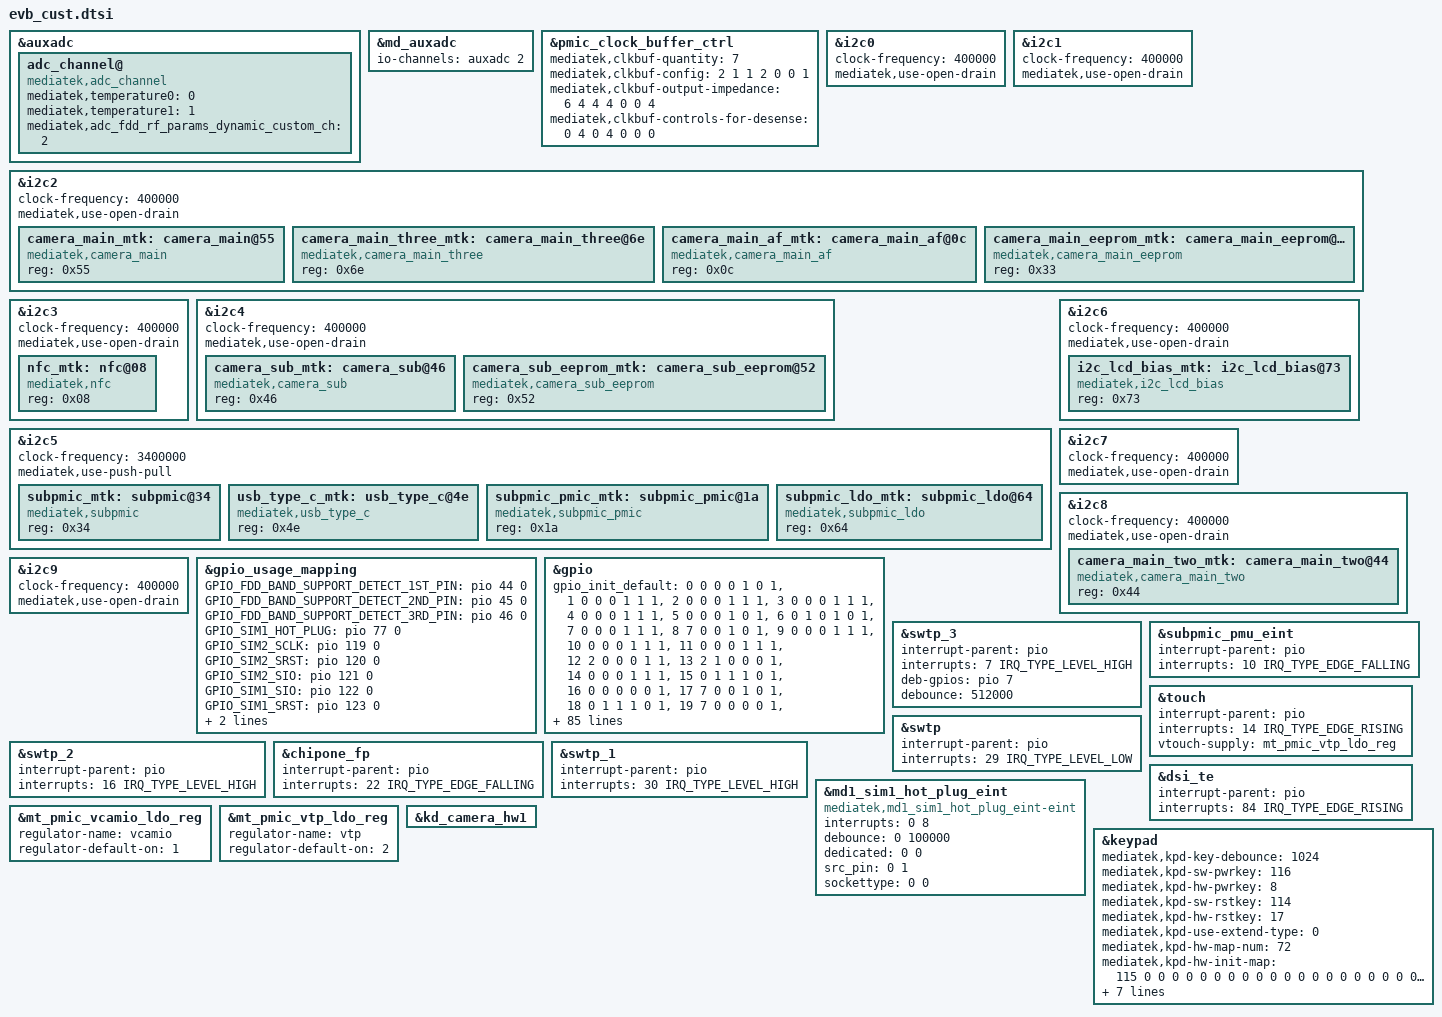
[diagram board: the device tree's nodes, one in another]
/*
 * Generated by MTK SP DrvGen Version: 3.5.160809 for MT6833.
 * 2023-02-21 14:04:30
 * Do Not Modify The File.
 * Copyright Mediatek Inc. (c) 2016.
*/

/*************************
 * ADC DTSI File
*************************/

&auxadc {
	adc_channel@ {
		compatible = "mediatek,adc_channel";
		mediatek,temperature0 = <0>;
		mediatek,temperature1 = <1>;
		mediatek,adc_fdd_rf_params_dynamic_custom_ch = <2>;
		status = "okay";
	};
};
&md_auxadc {
	io-channels = <&auxadc 2>;
};


/*************************
 * CLK_BUF DTSI File
*************************/

&pmic_clock_buffer_ctrl {
	mediatek,clkbuf-quantity = <7>;
	mediatek,clkbuf-config = <2 1 1 2 0 0 1>;
	mediatek,clkbuf-output-impedance = <6 4 4 4 0 0 4>;
	mediatek,clkbuf-controls-for-desense = <0 4 0 4 0 0 0>;
	status = "okay";
};


/*************************
 * I2C DTSI File
*************************/

&i2c0 {
	#address-cells = <1>;
	#size-cells = <0>;
	clock-frequency = <400000>;
	mediatek,use-open-drain;
};

&i2c1 {
	#address-cells = <1>;
	#size-cells = <0>;
	clock-frequency = <400000>;
	mediatek,use-open-drain;
};

&i2c2 {
	#address-cells = <1>;
	#size-cells = <0>;
	clock-frequency = <400000>;
	mediatek,use-open-drain;
	camera_main_mtk:camera_main@55 {
		compatible = "mediatek,camera_main";
		reg = <0x55>;
		status = "okay";
	};

	camera_main_three_mtk:camera_main_three@6e {
		compatible = "mediatek,camera_main_three";
		reg = <0x6e>;
		status = "okay";
	};

	camera_main_af_mtk:camera_main_af@0c {
		compatible = "mediatek,camera_main_af";
		reg = <0x0c>;
		status = "okay";
	};

	camera_main_eeprom_mtk:camera_main_eeprom@33 {
		compatible = "mediatek,camera_main_eeprom";
		reg = <0x33>;
		status = "okay";
	};

};

&i2c3 {
	#address-cells = <1>;
	#size-cells = <0>;
	clock-frequency = <400000>;
	mediatek,use-open-drain;
	nfc_mtk:nfc@08 {
		compatible = "mediatek,nfc";
		reg = <0x08>;
		status = "okay";
	};

};

&i2c4 {
	#address-cells = <1>;
	#size-cells = <0>;
	clock-frequency = <400000>;
	mediatek,use-open-drain;
	camera_sub_mtk:camera_sub@46 {
		compatible = "mediatek,camera_sub";
		reg = <0x46>;
		status = "okay";
	};

	camera_sub_eeprom_mtk:camera_sub_eeprom@52 {
		compatible = "mediatek,camera_sub_eeprom";
		reg = <0x52>;
		status = "okay";
	};

};

&i2c5 {
	#address-cells = <1>;
	#size-cells = <0>;
	clock-frequency = <3400000>;
	mediatek,use-push-pull;
	subpmic_mtk:subpmic@34 {
		compatible = "mediatek,subpmic";
		reg = <0x34>;
		status = "okay";
	};

	usb_type_c_mtk:usb_type_c@4e {
		compatible = "mediatek,usb_type_c";
		reg = <0x4e>;
		status = "okay";
	};

	subpmic_pmic_mtk:subpmic_pmic@1a {
		compatible = "mediatek,subpmic_pmic";
		reg = <0x1a>;
		status = "okay";
	};

	subpmic_ldo_mtk:subpmic_ldo@64 {
		compatible = "mediatek,subpmic_ldo";
		reg = <0x64>;
		status = "okay";
	};

};

&i2c6 {
	#address-cells = <1>;
	#size-cells = <0>;
	clock-frequency = <400000>;
	mediatek,use-open-drain;
	i2c_lcd_bias_mtk:i2c_lcd_bias@73 {
		compatible = "mediatek,i2c_lcd_bias";
		reg = <0x73>;
		status = "okay";
	};

};

&i2c7 {
	#address-cells = <1>;
	#size-cells = <0>;
	clock-frequency = <400000>;
	mediatek,use-open-drain;
};

&i2c8 {
	#address-cells = <1>;
	#size-cells = <0>;
	clock-frequency = <400000>;
	mediatek,use-open-drain;
	camera_main_two_mtk:camera_main_two@44 {
		compatible = "mediatek,camera_main_two";
		reg = <0x44>;
		status = "okay";
	};

};

&i2c9 {
	#address-cells = <1>;
	#size-cells = <0>;
	clock-frequency = <400000>;
	mediatek,use-open-drain;
};



/*************************
 * GPIO DTSI File
*************************/

&gpio_usage_mapping {
	GPIO_FDD_BAND_SUPPORT_DETECT_1ST_PIN = <&pio 44 0>;
	GPIO_FDD_BAND_SUPPORT_DETECT_2ND_PIN = <&pio 45 0>;
	GPIO_FDD_BAND_SUPPORT_DETECT_3RD_PIN = <&pio 46 0>;
	GPIO_SIM1_HOT_PLUG = <&pio 77 0>;
	GPIO_SIM2_SCLK = <&pio 119 0>;
	GPIO_SIM2_SRST = <&pio 120 0>;
	GPIO_SIM2_SIO = <&pio 121 0>;
	GPIO_SIM1_SIO = <&pio 122 0>;
	GPIO_SIM1_SRST = <&pio 123 0>;
	GPIO_SIM1_SCLK = <&pio 124 0>;
	GPIO_RF_PWREN_RST_PIN = <&pio 170 0>;
};

&gpio{
	gpio_init_default = <0 0 0 0 1 0 1>,
		<1 0 0 0 1 1 1>,
		<2 0 0 0 1 1 1>,
		<3 0 0 0 1 1 1>,
		<4 0 0 0 1 1 1>,
		<5 0 0 0 1 0 1>,
		<6 0 1 0 1 0 1>,
		<7 0 0 0 1 1 1>,
		<8 7 0 0 1 0 1>,
		<9 0 0 0 1 1 1>,
		<10 0 0 0 1 1 1>,
		<11 0 0 0 1 1 1>,
		<12 2 0 0 0 1 1>,
		<13 2 1 0 0 0 1>,
		<14 0 0 0 1 1 1>,
		<15 0 1 1 1 0 1>,
		<16 0 0 0 0 0 1>,
		<17 7 0 0 1 0 1>,
		<18 0 1 1 1 0 1>,
		<19 7 0 0 0 0 1>,
		<20 7 0 0 1 0 1>,
		<21 0 1 0 1 0 1>,
		<22 0 0 0 1 0 1>,
		<23 7 0 0 1 0 1>,
		<24 7 0 0 1 0 1>,
		<25 7 0 0 1 0 1>,
		<26 7 0 0 1 0 1>,
		<27 1 0 0 0 0 1>,
		<28 1 0 0 0 0 1>,
		<29 0 0 0 0 0 1>,
		<30 0 0 0 0 0 1>,
		<31 2 1 0 0 0 0>,
		<32 2 1 0 0 0 0>,
		<33 2 1 0 0 0 0>,
		<34 2 0 0 1 0 0>,
		<35 1 0 0 1 1 1>,
		<36 1 0 0 0 0 1>,
		<37 1 0 0 0 0 1>,
		<38 1 0 0 1 1 1>,
		<39 0 0 0 1 1 1>,
		<40 1 0 0 0 0 1>,
		<41 1 0 0 0 0 1>,
		<42 1 0 0 1 0 1>,
		<43 1 0 0 0 0 1>,
		<44 0 0 0 1 0 1>,
		<45 0 0 0 1 0 1>,
		<46 0 0 0 1 0 1>,
		<47 0 0 0 1 0 1>,
		<48 0 0 0 1 0 1>,
		<49 1 0 0 0 0 1>,
		<50 1 0 0 0 0 1>,
		<51 1 0 0 0 0 1>,
		<52 1 0 0 0 0 1>,
		<53 0 1 0 1 0 1>,
		<54 0 1 0 1 0 1>,
		<55 0 1 0 1 0 1>,
		<56 0 1 0 1 0 1>,
		<57 0 0 0 1 0 1>,
		<58 0 1 0 1 0 1>,
		<59 1 0 0 1 0 1>,
		<60 0 1 0 1 0 1>,
		<61 1 0 0 1 1 1>,
		<62 1 0 0 0 0 1>,
		<63 1 0 0 1 1 1>,
		<64 1 0 0 0 0 1>,
		<77 1 0 0 1 1 1>,
		<78 0 0 0 1 0 1>,
		<79 1 0 0 1 1 1>,
		<80 0 1 0 1 0 1>,
		<81 3 0 0 1 0 1>,
		<82 0 1 0 1 0 1>,
		<83 1 0 0 0 0 1>,
		<84 1 0 0 1 0 1>,
		<85 1 0 0 1 0 1>,
		<86 0 0 0 1 0 1>,
		<87 1 1 0 1 0 1>,
		<88 1 1 0 1 0 1>,
		<89 1 1 0 1 0 1>,
		<90 1 1 0 0 0 1>,
		<91 1 1 0 1 0 1>,
		<92 1 1 0 1 0 1>,
		<93 0 1 0 1 0 1>,
		<94 0 1 0 1 0 1>,
		<95 1 0 0 1 0 1>,
		<96 1 0 0 1 0 1>,
		<97 2 1 0 0 0 1>,
		<98 2 1 0 0 0 1>,
		<99 2 0 0 1 1 1>,
		<100 2 0 0 1 1 1>,
		<101 1 0 0 1 1 1>,
		<102 1 0 0 1 1 1>,
		<103 1 0 0 1 1 1>,
		<104 1 0 0 1 1 1>,
		<105 1 0 0 1 1 1>,
		<106 1 0 0 1 1 1>,
		<107 1 0 0 1 1 1>,
		<108 1 0 0 1 1 1>,
		<109 1 0 0 1 1 1>,
		<110 1 0 0 1 1 1>,
		<111 1 0 0 1 1 1>,
		<112 1 0 0 1 1 1>,
		<113 1 0 0 1 1 1>,
		<114 1 0 0 1 1 1>,
		<115 1 0 0 1 0 1>,
		<116 1 0 0 1 0 1>,
		<117 0 0 0 1 0 1>,
		<118 0 0 0 1 0 1>,
		<119 1 0 0 0 0 1>,
		<120 1 0 0 0 0 1>,
		<121 1 0 0 1 1 1>,
		<122 1 0 0 1 1 1>,
		<123 1 0 0 0 0 1>,
		<124 1 0 0 0 0 1>,
		<125 1 0 0 0 0 1>,
		<126 1 0 0 1 1 1>,
		<127 1 0 0 1 1 1>,
		<128 1 0 0 1 1 1>,
		<129 1 0 0 1 1 1>,
		<130 1 0 0 1 1 1>,
		<131 0 1 1 1 0 1>,
		<132 0 0 0 0 0 1>,
		<133 0 1 0 1 0 1>,
		<134 0 1 0 1 0 1>,
		<135 0 1 0 1 0 1>,
		<136 0 1 1 1 0 1>,
		<137 0 1 0 1 0 1>,
		<138 0 1 0 1 0 1>,
		<139 0 1 0 1 0 1>,
		<140 0 1 0 1 0 1>,
		<141 1 0 0 0 0 1>,
		<142 1 0 0 0 0 1>,
		<143 1 0 0 0 0 1>,
		<144 1 0 0 0 0 1>,
		<145 1 0 0 0 0 1>,
		<146 1 0 0 0 0 1>,
		<147 1 0 0 0 0 1>,
		<148 1 0 0 0 0 1>,
		<149 1 0 0 1 0 1>,
		<150 1 0 0 1 0 1>,
		<151 1 0 0 1 0 1>,
		<152 1 0 0 1 0 1>,
		<153 1 0 0 0 0 1>,
		<154 1 0 0 0 0 1>,
		<155 1 0 0 0 0 1>,
		<156 1 0 0 0 0 1>,
		<157 1 0 0 0 0 1>,
		<158 1 0 0 0 0 1>,
		<159 1 0 0 1 0 1>,
		<160 1 0 0 1 0 1>,
		<161 1 0 0 1 0 1>,
		<162 1 0 0 0 0 0>,
		<163 1 0 0 1 0 0>,
		<164 1 0 0 1 0 1>,
		<165 1 0 0 1 0 1>,
		<166 1 0 0 0 0 1>,
		<167 1 0 0 0 0 1>,
		<168 1 0 0 0 0 1>,
		<169 0 0 0 1 0 1>,
		<170 0 1 1 1 0 1>,
		<171 1 0 0 0 0 1>,
		<172 1 0 0 0 0 1>,
		<173 1 0 0 0 0 1>,
		<174 1 0 0 0 0 1>,
		<175 1 0 0 0 0 1>,
		<176 1 0 0 0 0 1>,
		<177 1 0 0 0 0 1>,
		<178 1 0 0 0 0 1>,
		<179 1 0 0 0 0 1>,
		<180 1 0 0 0 0 1>,
		<181 1 0 0 0 0 1>,
		<182 1 0 0 0 0 1>,
		<183 1 0 0 0 0 1>,
		<184 1 0 0 0 0 1>,
		<185 1 0 0 0 0 1>,
		<186 1 0 0 0 0 1>,
		<187 1 0 0 0 0 1>,
		<188 1 0 0 0 0 0>,
		<189 1 0 0 1 0 0>,
		<190 1 0 0 0 0 0>,
		<191 1 0 0 1 0 0>,
		<192 0 0 0 1 0 1>,
		<193 0 0 0 1 0 1>,
		<194 0 0 0 1 0 1>,
		<195 0 0 0 1 0 1>,
		<196 0 0 0 1 0 1>,
		<197 0 0 0 1 0 1>,
		<198 0 0 0 1 0 1>,
		<199 0 0 0 1 0 1>,
		<200 0 0 0 1 0 1>;
};


/*************************
 * EINT DTSI File
*************************/

#include <dt-bindings/interrupt-controller/irq.h>
#include <dt-bindings/interrupt-controller/arm-gic.h>

&swtp_3 {
	interrupt-parent = <&pio>;
	interrupts = <7 IRQ_TYPE_LEVEL_HIGH>;
	deb-gpios = <&pio 7 0>;
	debounce = <512000>;
	status = "okay";
};

&subpmic_pmu_eint {
	interrupt-parent = <&pio>;
	interrupts = <10 IRQ_TYPE_EDGE_FALLING>;
	status = "okay";
};

&touch {
	interrupt-parent = <&pio>;
	interrupts = <14 IRQ_TYPE_EDGE_RISING>;
	status = "okay";
};

&swtp_2 {
	interrupt-parent = <&pio>;
	interrupts = <16 IRQ_TYPE_LEVEL_HIGH>;
	status = "okay";
};

&chipone_fp {
	interrupt-parent = <&pio>;
	interrupts = <22 IRQ_TYPE_EDGE_FALLING>;
	status = "okay";
};

&swtp {
	interrupt-parent = <&pio>;
	interrupts = <29 IRQ_TYPE_LEVEL_LOW>;
	status = "okay";
};

&swtp_1 {
	interrupt-parent = <&pio>;
	interrupts = <30 IRQ_TYPE_LEVEL_HIGH>;
	status = "okay";
};

&dsi_te {
	interrupt-parent = <&pio>;
	interrupts = <84 IRQ_TYPE_EDGE_RISING>;
	status = "okay";
};



/*************************
 * MD1_EINT DTSI File
*************************/

&md1_sim1_hot_plug_eint {
	compatible = "mediatek,md1_sim1_hot_plug_eint-eint";
	interrupts = <0 8>;
	debounce = <0 100000>;
	dedicated = <0 0>;
	src_pin = <0 1>;
	sockettype = <0 0>;
	status = "okay";
};



/*************************
 * PMIC DTSI File
*************************/

&mt_pmic_vcamio_ldo_reg {
	regulator-name = "vcamio";
	regulator-default-on = <1>; /* 0:skip, 1: off, 2:on */
	status = "okay";
};
&mt_pmic_vtp_ldo_reg {
	regulator-name = "vtp";
	regulator-default-on = <2>; /* 0:skip, 1: off, 2:on */
	status = "okay";
};

&kd_camera_hw1 {
	status = "okay";
};

&touch {
	vtouch-supply = <&mt_pmic_vtp_ldo_reg>;
	status = "okay";
};


/*************************
 * POWER DTSI File
*************************/



/*************************
 * KPD DTSI File
*************************/

&keypad {
	mediatek,kpd-key-debounce = <1024>;
	mediatek,kpd-sw-pwrkey = <116>;
	mediatek,kpd-hw-pwrkey = <8>;
	mediatek,kpd-sw-rstkey  = <114>;
	mediatek,kpd-hw-rstkey = <17>;
	mediatek,kpd-use-extend-type = <0>;
	/*HW Keycode [0~71] -> Linux Keycode*/
	mediatek,kpd-hw-map-num = <72>;
	mediatek,kpd-hw-init-map = <115 0 0 0 0 0 0 0 0 0 0 0 0 0 0 0 0 0 0 0 0 0 0 0 0 0 0 0 0 0 0 0 0 0 0 0 0 0 0 0 0 0 0 0 0 0 0 0 0 0 0 0 0 0 0 0 0 0 0 0 0 0 0 0 0 0 0 0 0 0 0 0 >;
	mediatek,kpd-pwrkey-eint-gpio = <0>;
	mediatek,kpd-pwkey-gpio-din  = <0>;
	mediatek,kpd-hw-dl-key0 = <17>;
	mediatek,kpd-hw-dl-key1 = <0>;
	mediatek,kpd-hw-dl-key2 = <8>;
	mediatek,kpd-hw-recovery-key = <17>;
	mediatek,kpd-hw-factory-key = <0>;
	status = "okay";
};


